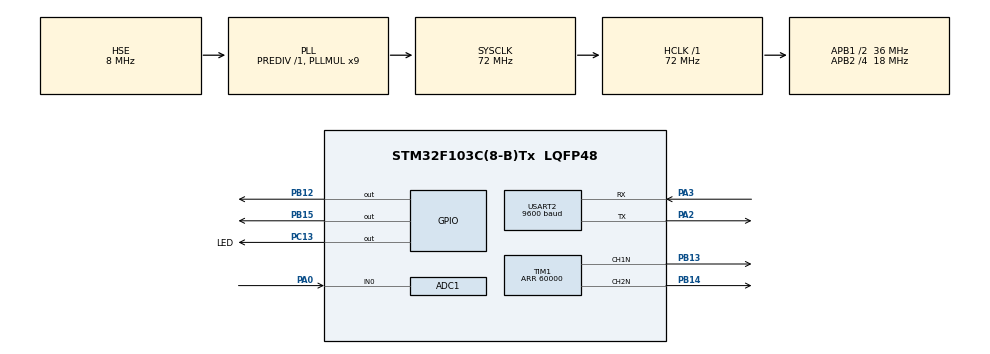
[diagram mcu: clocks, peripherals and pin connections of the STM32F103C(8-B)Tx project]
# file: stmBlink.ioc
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ADC1.Channel-0\#ChannelRegularConversion=ADC_CHANNEL_0
ADC1.ContinuousConvMode=ENABLE
ADC1.NbrOfConversionFlag=1
ADC1.Rank-0\#ChannelRegularConversion=1
ADC1.SamplingTime-0\#ChannelRegularConversion=ADC_SAMPLETIME_1CYCLE_5
ADC1.master=1
Mcu.Family=STM32F1
Mcu.Name=STM32F103C(8-B)Tx
Mcu.Package=LQFP48
NVIC.PriorityGroup=NVIC_PRIORITYGROUP_4
NVIC.TIM1_CC_IRQn=true\:0\:0\:false\:false\:true\:true
PA0-WKUP.Signal=ADCx_IN0
PA13.Mode=Serial_Wire
PA13.Signal=SYS_JTMS-SWDIO
PA14.Mode=Serial_Wire
PA14.Signal=SYS_JTCK-SWCLK
PA2.Mode=Asynchronous
PA2.Signal=USART2_TX
PA3.Mode=Asynchronous
PA3.Signal=USART2_RX
PB12.Signal=GPIO_Output
PB13.Mode=PWM Generation1 CH1N
PB13.Signal=TIM1_CH1N
PB14.Mode=PWM Generation2 CH2N
PB14.Signal=TIM1_CH2N
PB15.Signal=GPIO_Output
PC13-TAMPER-RTC.GPIO_Label=LED
PC13-TAMPER-RTC.Signal=GPIO_Output
PD0-OSC_IN.Mode=HSE-External-Oscillator
PD0-OSC_IN.Signal=RCC_OSC_IN
PD1-OSC_OUT.Mode=HSE-External-Oscillator
PD1-OSC_OUT.Signal=RCC_OSC_OUT
ProjectManager.HeapSize=0x200
ProjectManager.StackSize=0x400
ProjectManager.TargetToolchain=Makefile
RCC.AHBFreq_Value=72000000
RCC.APB1CLKDivider=RCC_HCLK_DIV2
RCC.APB1Freq_Value=36000000
RCC.APB1TimFreq_Value=72000000
RCC.APB2CLKDivider=RCC_HCLK_DIV4
RCC.APB2Freq_Value=18000000
RCC.APB2TimFreq_Value=36000000
RCC.HCLKFreq_Value=72000000
RCC.PLLMUL=RCC_PLL_MUL9
RCC.PLLSourceVirtual=RCC_PLLSOURCE_HSE
RCC.SYSCLKFreq_VALUE=72000000
RCC.SYSCLKSource=RCC_SYSCLKSOURCE_PLLCLK
RCC.USBFreq_Value=48000000
RCC.USBPrescaler=RCC_USBCLKSOURCE_PLL_DIV1_5
SH.ADCx_IN0.0=ADC1_IN0,IN0
TIM1.Channel-PWM\ Generation1\ CH1N=TIM_CHANNEL_1
TIM1.Channel-PWM\ Generation2\ CH2N=TIM_CHANNEL_2
TIM1.Period=60000
TIM1.Pulse-PWM\ Generation1\ CH1N=2000
TIM1.Pulse-PWM\ Generation2\ CH2N=2000
USART2.BaudRate=9600
USART2.VirtualMode=VM_ASYNC
board=custom

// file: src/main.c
/* USER CODE BEGIN Header */
/**
  ******************************************************************************
  * @file           : main.c
  * @brief          : Main program body
  ******************************************************************************
  ** This notice applies to any and all portions of this file
  * that are not between comment pairs USER CODE BEGIN and
  * USER CODE END. Other portions of this file, whether
  * inserted by the user or by software development tools
  * are owned by their respective copyright owners.
  *
  * COPYRIGHT(c) 2019 STMicroelectronics
  *
  * Redistribution and use in source and binary forms, with or without modification,
  * are permitted provided that the following conditions are met:
  *   1. Redistributions of source code must retain the above copyright notice,
  *      this list of conditions and the following disclaimer.
  *   2. Redistributions in binary form must reproduce the above copyright notice,
  *      this list of conditions and the following disclaimer in the documentation
  *      and/or other materials provided with the distribution.
  *   3. Neither the name of STMicroelectronics nor the names of its contributors
  *      may be used to endorse or promote products derived from this software
  *      without specific prior written permission.
  *
  * THIS SOFTWARE IS PROVIDED BY THE COPYRIGHT HOLDERS AND CONTRIBUTORS "AS IS"
  * AND ANY EXPRESS OR IMPLIED WARRANTIES, INCLUDING, BUT NOT LIMITED TO, THE
  * IMPLIED WARRANTIES OF MERCHANTABILITY AND FITNESS FOR A PARTICULAR PURPOSE ARE
  * DISCLAIMED. IN NO EVENT SHALL THE COPYRIGHT HOLDER OR CONTRIBUTORS BE LIABLE
  * FOR ANY DIRECT, INDIRECT, INCIDENTAL, SPECIAL, EXEMPLARY, OR CONSEQUENTIAL
  * DAMAGES (INCLUDING, BUT NOT LIMITED TO, PROCUREMENT OF SUBSTITUTE GOODS OR
  * SERVICES; LOSS OF USE, DATA, OR PROFITS; OR BUSINESS INTERRUPTION) HOWEVER
  * CAUSED AND ON ANY THEORY OF LIABILITY, WHETHER IN CONTRACT, STRICT LIABILITY,
  * OR TORT (INCLUDING NEGLIGENCE OR OTHERWISE) ARISING IN ANY WAY OUT OF THE USE
  * OF THIS SOFTWARE, EVEN IF ADVISED OF THE POSSIBILITY OF SUCH DAMAGE.
  *
  ******************************************************************************
  */
/* USER CODE END Header */

#include "main.h"
#include "adc.h"
#include "tim.h"
#include "usart.h"
#include "gpio.h"

/* USER CODE BEGIN Includes */
#include "medianFilter.h"
/* USER CODE END Includes */

void SystemClock_Config(void);

int main(void)
{

  /* MCU Configuration--------------------------------------------------------*/

  /* Reset of all peripherals, Initializes the Flash interface and the Systick. */
  HAL_Init();

  /* Configure the system clock */
  SystemClock_Config();

  /* Initialize all configured peripherals */
  MX_GPIO_Init();
  MX_USART2_UART_Init();
  MX_TIM1_Init();
  MX_ADC1_Init();
  /* USER CODE BEGIN 2 */
  //char sendStr[16];

  HAL_TIMEx_PWMN_Start(&htim1, TIM_CHANNEL_1);
  HAL_TIMEx_PWMN_Start(&htim1, TIM_CHANNEL_2);

  uint8_t str[16] = {0};

  /* USER CODE END 2 */

  /* Infinite loop */
  while (1)
  {

    /* USER CODE BEGIN 3 */

    /*
    encoder code
    capture = TIM4->CNT;
    encoder += capture - capture_prev;

    if(abs(capture-capture_prev)>32767){
      encoder += (capture < capture_prev ? 65535 : -65535);
      HAL_GPIO_TogglePin(LED_GPIO_Port, LED_Pin);
    }

    //sprintf(sendStr, "Encoder: %d \r\n", encoder);

    //HAL_UART_Transmit(&huart2, sendStr, 16, 0xFFF);

    capture_prev = capture;
    HAL_Delay(100);
    */

    //control motor
    /*
    HAL_GPIO_WritePin(GPIOB, GPIO_PIN_12, GPIO_PIN_SET);
    HAL_GPIO_WritePin(GPIOB, GPIO_PIN_15, GPIO_PIN_SET);
    for(int  i = 0; i < 65535; i+=1000){
      TIM1->CCR1 = i;
      TIM1->CCR2 = i;
      HAL_Delay(50);
    }*/

    float i = readMedian(hadc1, 15);

    sprintf(str, "%f\r\n", i);
    HAL_UART_Transmit(&huart2, str, 16, 0xFFF);
    HAL_Delay(100);

  }
  /* USER CODE END 3 */
}

void SystemClock_Config(void)
{
  RCC_OscInitTypeDef RCC_OscInitStruct = {0};
  RCC_ClkInitTypeDef RCC_ClkInitStruct = {0};
  RCC_PeriphCLKInitTypeDef PeriphClkInit = {0};

  /**Initializes the CPU, AHB and APB busses clocks
  */
  RCC_OscInitStruct.OscillatorType = RCC_OSCILLATORTYPE_HSE;
  RCC_OscInitStruct.HSEState = RCC_HSE_ON;
  RCC_OscInitStruct.HSEPredivValue = RCC_HSE_PREDIV_DIV1;
  RCC_OscInitStruct.HSIState = RCC_HSI_ON;
  RCC_OscInitStruct.PLL.PLLState = RCC_PLL_ON;
  RCC_OscInitStruct.PLL.PLLSource = RCC_PLLSOURCE_HSE;
  RCC_OscInitStruct.PLL.PLLMUL = RCC_PLL_MUL9;
  if (HAL_RCC_OscConfig(&RCC_OscInitStruct) != HAL_OK)
  {
    Error_Handler();
  }
  /**Initializes the CPU, AHB and APB busses clocks
  */
  RCC_ClkInitStruct.ClockType = RCC_CLOCKTYPE_HCLK|RCC_CLOCKTYPE_SYSCLK
                              |RCC_CLOCKTYPE_PCLK1|RCC_CLOCKTYPE_PCLK2;
  RCC_ClkInitStruct.SYSCLKSource = RCC_SYSCLKSOURCE_PLLCLK;
  RCC_ClkInitStruct.AHBCLKDivider = RCC_SYSCLK_DIV1;
  RCC_ClkInitStruct.APB1CLKDivider = RCC_HCLK_DIV2;
  RCC_ClkInitStruct.APB2CLKDivider = RCC_HCLK_DIV4;

  if (HAL_RCC_ClockConfig(&RCC_ClkInitStruct, FLASH_LATENCY_2) != HAL_OK)
  {
    Error_Handler();
  }
  PeriphClkInit.PeriphClockSelection = RCC_PERIPHCLK_ADC;
  PeriphClkInit.AdcClockSelection = RCC_ADCPCLK2_DIV2;
  if (HAL_RCCEx_PeriphCLKConfig(&PeriphClkInit) != HAL_OK)
  {
    Error_Handler();
  }
}

void Error_Handler(void)
{
}

/************************ (C) COPYRIGHT STMicroelectronics *****END OF FILE****/
